# STM32L021K4U6 register map
File version: 1.0
STM32L021D4P3,STM32L021D4P6,STM32L021D4P7,STM32L021F4P6,STM32L021F4U6,STM32L021F4U7,STM32L021G4U6,STM32L021G4U7,STM32L021K4T6,STM32L021K4T7,STM32L021K4U6
Registers are 32-bit, access not given, reset 0x0 unless marked. A register's access mark holds for its fields unless they carry their own. Offsets are from the block's base; lines under a group give offsets from that group; [hi:lo] are bit positions; {n}, {i} and the like mark numbered series; 'fields as' and 'values as' point back to an identical list; <NAME> marks a mode.

## Memory map
0x1FF80000 OB
0x40000000 TIM2
0x40002800 RTC
0x40002C00 WWDG
0x40003000 IWDG
0x40004400 USART2
0x40004800 LPUART1
0x40005400 I2C1
0x40007000 PWR
0x40007C00 LPTIM1
0x40010000 SYSCFG
0x40010018 COMP12_COMMON
0x40010018 COMP1
0x4001001C COMP2
0x40010400 EXTI
0x40010800 TIM21
0x40012400 ADC1
0x40020000 DMA1
0x400200A8 DMA1_CSELR
0x40021000 RCC
0x40022000 FLASH
0x40023000 CRC
0x40026000 AES
0x50000000 GPIOA
0x50000400 GPIOB
0x50000800 GPIOC

## OB
Base 0x1FF80000
0x00 RDP
0x04 USER
0x08 WRP01

## TIM2
Base 0x40000000
Same registers: TIM21 0x40010800
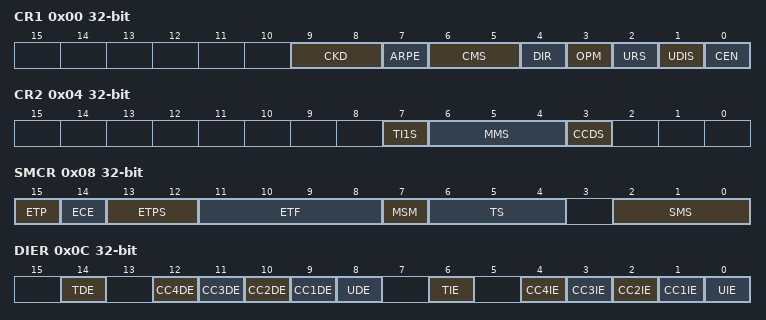
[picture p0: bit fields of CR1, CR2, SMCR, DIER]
0x00 CR1
  [9:8] CKD, [7] ARPE, [6:5] CMS, [4] DIR, [3] OPM, [2] URS, [1] UDIS, [0] CEN
0x04 CR2
  [7] TI1S, [6:4] MMS, [3] CCDS
0x08 SMCR
  [15] ETP, [14] ECE, [13:12] ETPS, [11:8] ETF, [7] MSM, [6:4] TS, [2:0] SMS
0x0C DIER
  [14] TDE, [n+8] CC{n}DE (n=1..4), [8] UDE, [6] TIE, [n] CC{n}IE (n=1..4), [0] UIE
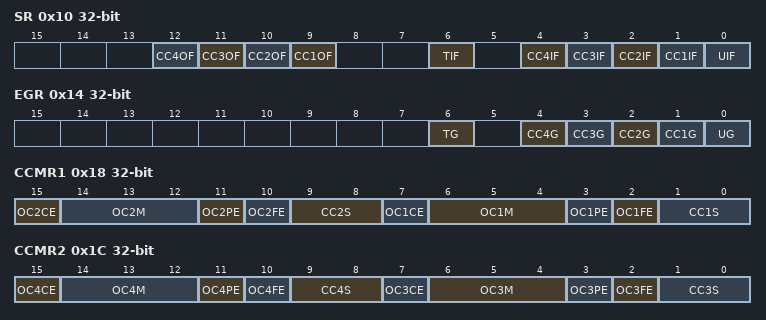
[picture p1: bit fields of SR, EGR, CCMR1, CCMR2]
0x10 SR
  [n+8] CC{n}OF (n=1..4), [6] TIF, [n] CC{n}IF (n=1..4), [0] UIF
0x14 EGR
  [6] TG, [n] CC{n}G (n=1..4), [0] UG
0x18 CCMR1
  [15] OC2CE, [14:12] OC2M, [11] OC2PE, [10] OC2FE, [9:8] CC2S, [7] OC1CE, [6:4] OC1M, [3] OC1PE, [2] OC1FE, [1:0] CC1S
0x1C CCMR2
  [15] OC4CE, [14:12] OC4M, [11] OC4PE, [10] OC4FE, [9:8] CC4S, [7] OC3CE, [6:4] OC3M, [3] OC3PE, [2] OC3FE, [1:0] CC3S
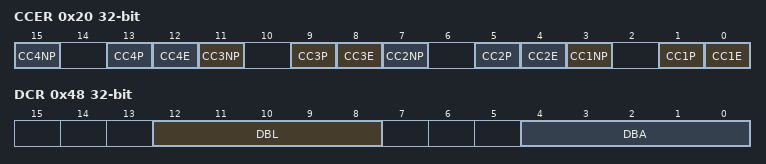
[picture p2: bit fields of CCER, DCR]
0x20 CCER
  [4n-1] CC{n}NP (n=1..4), [4n-3] CC{n}P (n=1..4), [4n-4] CC{n}E (n=1..4)
0x24 CNT
  [15:0] CNT
0x28 PSC
  [15:0] PSC
0x2C ARR
  [15:0] ARR
{0x30+4i} CCR{i} (i=1..4)
  [15:0] CCR{i}
0x48 DCR
  [12:8] DBL, [4:0] DBA
0x4C DMAR
  [15:0] DMAB
0x50 OR

## RTC
Base 0x40002800
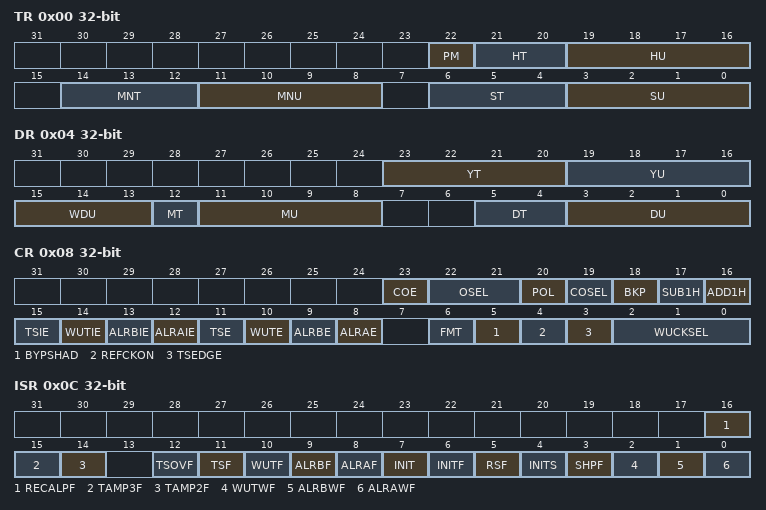
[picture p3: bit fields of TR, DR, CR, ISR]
0x00 TR
  [22] PM, [21:20] HT, [19:16] HU, [14:12] MNT, [11:8] MNU, [6:4] ST, [3:0] SU
0x04 DR
  [23:20] YT, [19:16] YU, [15:13] WDU, [12] MT, [11:8] MU, [5:4] DT, [3:0] DU
0x08 CR
  [23] COE, [22:21] OSEL, [20] POL, [19] COSEL, [18] BKP, [17] SUB1H, [16] ADD1H, [15] TSIE, [14] WUTIE, [13] ALRBIE, [12] ALRAIE, [11] TSE, [10] WUTE, [9] ALRBE, [8] ALRAE, [6] FMT, [5] BYPSHAD, [4] REFCKON, [3] TSEDGE, [2:0] WUCKSEL
0x0C ISR
  [16] RECALPF, [15] TAMP3F, [14] TAMP2F, [12] TSOVF, [11] TSF, [10] WUTF, [9] ALRBF, [8] ALRAF, [7] INIT, [6] INITF, [5] RSF, [4] INITS, [3] SHPF, [2] WUTWF, [1] ALRBWF, [0] ALRAWF
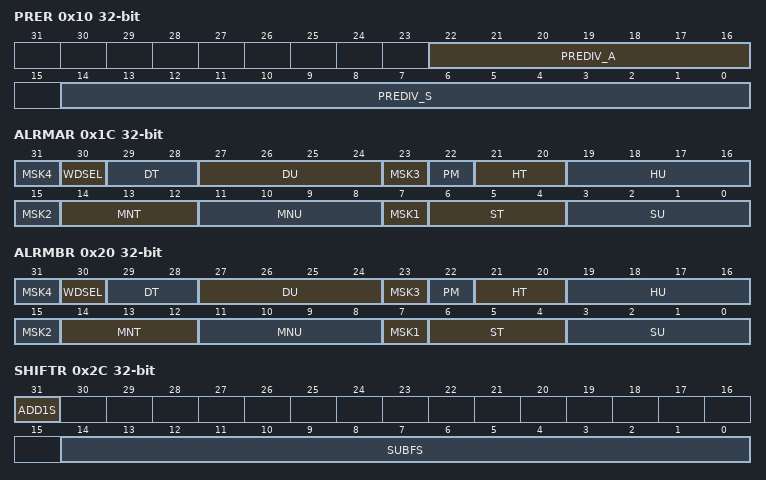
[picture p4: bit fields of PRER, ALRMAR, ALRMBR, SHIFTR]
0x10 PRER
  [22:16] PREDIV_A, [14:0] PREDIV_S
0x14 WUTR
  [15:0] WUT
0x1C ALRMAR
  [8n-1] MSK{n} (n=1..4), [30] WDSEL, [29:28] DT, [27:24] DU, [22] PM, [21:20] HT, [19:16] HU, [14:12] MNT, [11:8] MNU, [6:4] ST, [3:0] SU
0x20 ALRMBR
  fields as ALRMAR
0x24 WPR
  [7:0] KEY
0x28 SSR
  [15:0] SS
0x2C SHIFTR
  [31] ADD1S, [14:0] SUBFS
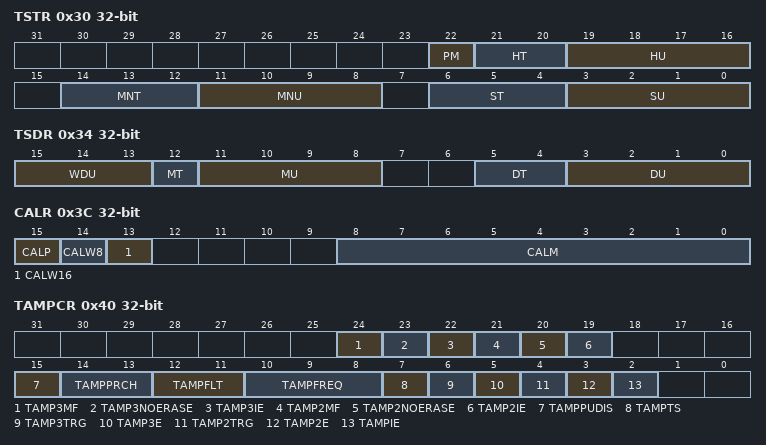
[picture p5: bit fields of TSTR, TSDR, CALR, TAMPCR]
0x30 TSTR
  fields as TR
0x34 TSDR
  [15:13] WDU, [12] MT, [11:8] MU, [5:4] DT, [3:0] DU
0x38 TSSSR
  [15:0] SS
0x3C CALR
  [15] CALP, [14] CALW8, [13] CALW16, [8:0] CALM
0x40 TAMPCR
  [24] TAMP3MF, [23] TAMP3NOERASE, [22] TAMP3IE, [21] TAMP2MF, [20] TAMP2NOERASE, [19] TAMP2IE, [15] TAMPPUDIS, [14:13] TAMPPRCH, [12:11] TAMPFLT, [10:8] TAMPFREQ, [7] TAMPTS, [6] TAMP3TRG, [5] TAMP3E, [4] TAMP2TRG, [3] TAMP2E, [2] TAMPIE
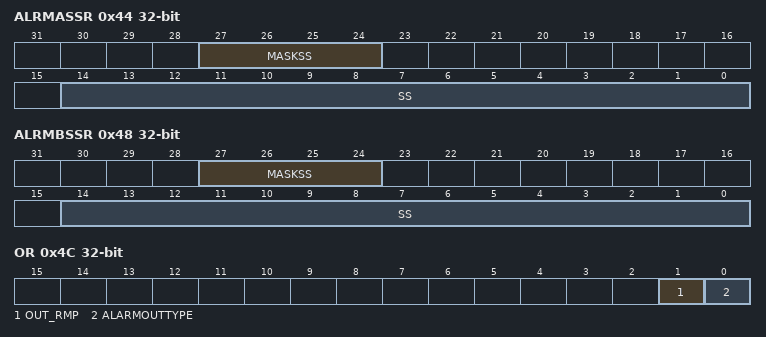
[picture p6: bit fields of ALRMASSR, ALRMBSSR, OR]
0x44 ALRMASSR
  [27:24] MASKSS, [14:0] SS
0x48 ALRMBSSR
  [27:24] MASKSS, [14:0] SS
0x4C OR
  [1] OUT_RMP, [0] ALARMOUTTYPE
{0x50+4i} BKP{i}R (i=0..4)

## WWDG
Base 0x40002C00
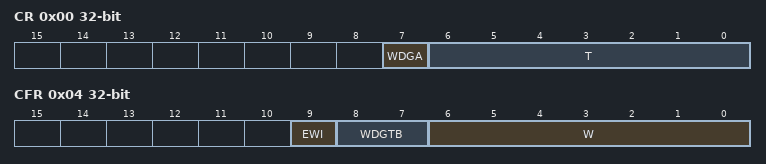
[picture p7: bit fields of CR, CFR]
0x00 CR
  [7] WDGA, [6:0] T
0x04 CFR
  [9] EWI, [8:7] WDGTB, [6:0] W
0x08 SR
  [0] EWIF

## IWDG
Base 0x40003000
0x00 KR
  [15:0] KEY
0x04 PR
  [2:0] PR
0x08 RLR
  [11:0] RL
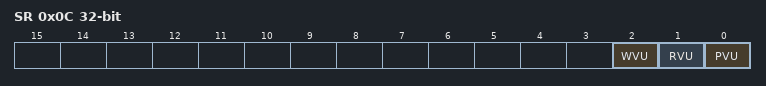
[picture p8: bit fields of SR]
0x0C SR
  [2] WVU, [1] RVU, [0] PVU
0x10 WINR
  [11:0] WIN

## USART2
Base 0x40004400
Same registers: LPUART1 0x40004800
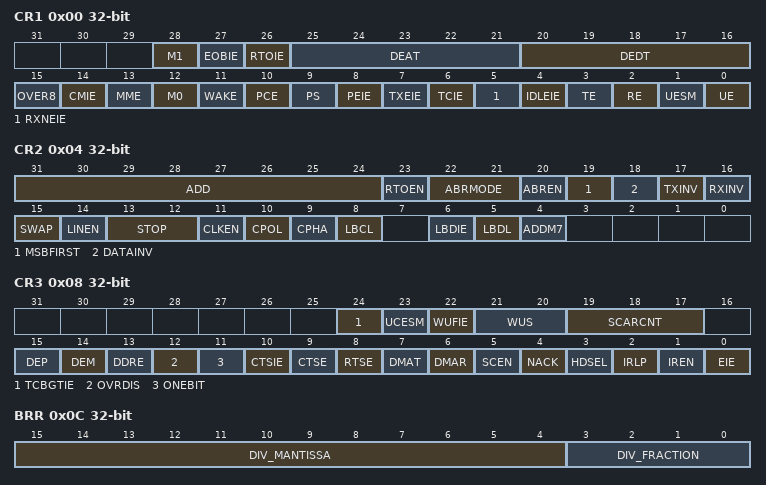
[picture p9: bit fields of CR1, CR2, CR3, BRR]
0x00 CR1
  [28] M1, [27] EOBIE, [26] RTOIE, [25:21] DEAT, [20:16] DEDT, [15] OVER8, [14] CMIE, [13] MME, [12] M0, [11] WAKE, [10] PCE, [9] PS, [8] PEIE, [7] TXEIE, [6] TCIE, [5] RXNEIE, [4] IDLEIE, [3] TE, [2] RE, [1] UESM, [0] UE
0x04 CR2
  [31:24] ADD, [23] RTOEN, [22:21] ABRMODE, [20] ABREN, [19] MSBFIRST, [18] DATAINV, [17] TXINV, [16] RXINV, [15] SWAP, [14] LINEN, [13:12] STOP, [11] CLKEN, [10] CPOL, [9] CPHA, [8] LBCL, [6] LBDIE, [5] LBDL, [4] ADDM7
0x08 CR3
  [24] TCBGTIE, [23] UCESM, [22] WUFIE, [21:20] WUS, [19:17] SCARCNT, [15] DEP, [14] DEM, [13] DDRE, [12] OVRDIS, [11] ONEBIT, [10] CTSIE, [9] CTSE, [8] RTSE, [7] DMAT, [6] DMAR, [5] SCEN, [4] NACK, [3] HDSEL, [2] IRLP, [1] IREN, [0] EIE
0x0C BRR
  [15:4] DIV_MANTISSA, [3:0] DIV_FRACTION
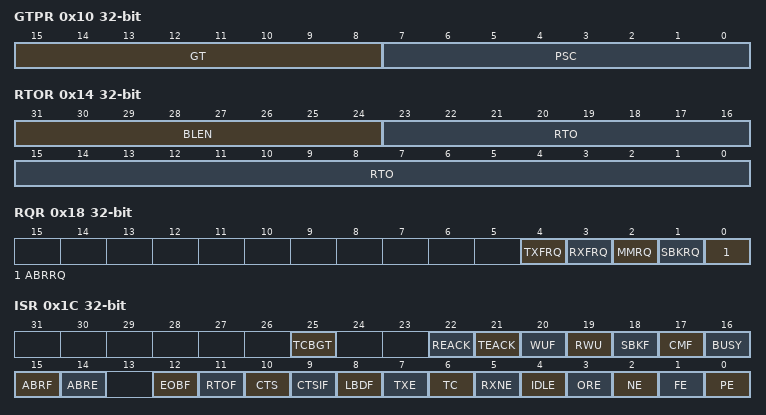
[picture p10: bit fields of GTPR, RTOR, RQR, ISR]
0x10 GTPR
  [15:8] GT, [7:0] PSC
0x14 RTOR
  [31:24] BLEN, [23:0] RTO
0x18 RQR
  [4] TXFRQ, [3] RXFRQ, [2] MMRQ, [1] SBKRQ, [0] ABRRQ
0x1C ISR
  [25] TCBGT, [22] REACK, [21] TEACK, [20] WUF, [19] RWU, [18] SBKF, [17] CMF, [16] BUSY, [15] ABRF, [14] ABRE, [12] EOBF, [11] RTOF, [10] CTS, [9] CTSIF, [8] LBDF, [7] TXE, [6] TC, [5] RXNE, [4] IDLE, [3] ORE, [2] NE, [1] FE, [0] PE
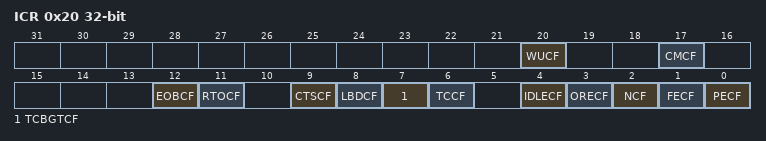
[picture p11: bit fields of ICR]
0x20 ICR
  [20] WUCF, [17] CMCF, [12] EOBCF, [11] RTOCF, [9] CTSCF, [8] LBDCF, [7] TCBGTCF, [6] TCCF, [4] IDLECF, [3] ORECF, [2] NCF, [1] FECF, [0] PECF
0x24 RDR
  [8:0] RDR
0x28 TDR
  [8:0] TDR
